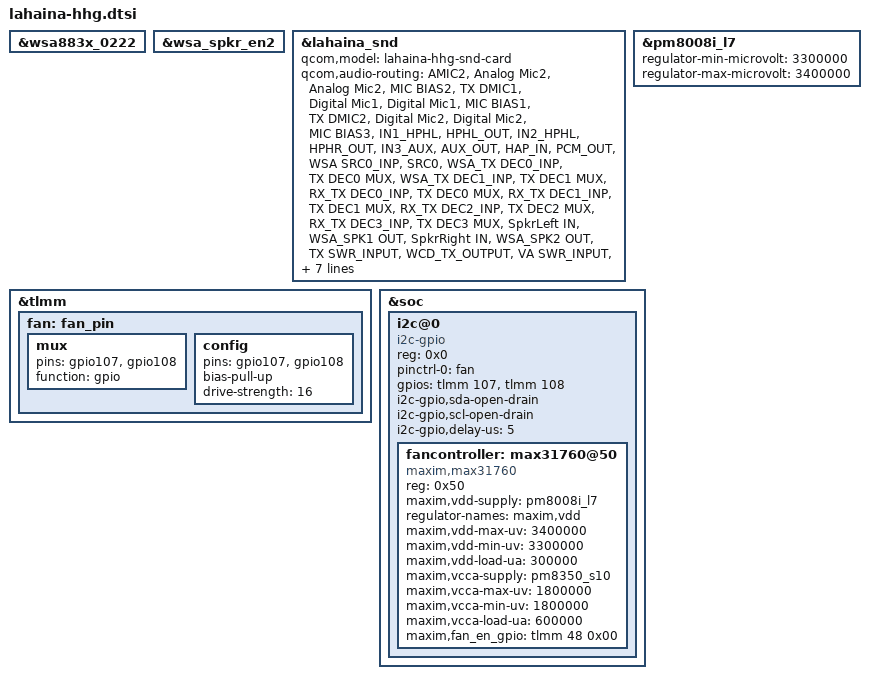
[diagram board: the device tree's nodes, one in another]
#include "lahaina-hdk.dtsi"

&wsa883x_0222 {
	status = "ok";
};

&wsa_spkr_en2 {
	status = "ok";
};

&lahaina_snd {
	qcom,model = "lahaina-hhg-snd-card";

	qcom,audio-routing =
		"AMIC2", "Analog Mic2",
		"Analog Mic2", "MIC BIAS2",
		"TX DMIC1", "Digital Mic1",
		"Digital Mic1", "MIC BIAS1",
		"TX DMIC2", "Digital Mic2",
		"Digital Mic2", "MIC BIAS3",
		"IN1_HPHL", "HPHL_OUT",
		"IN2_HPHL", "HPHR_OUT",
		"IN3_AUX", "AUX_OUT",
		"HAP_IN", "PCM_OUT",
		"WSA SRC0_INP", "SRC0",
		"WSA_TX DEC0_INP", "TX DEC0 MUX",
		"WSA_TX DEC1_INP", "TX DEC1 MUX",
		"RX_TX DEC0_INP", "TX DEC0 MUX",
		"RX_TX DEC1_INP", "TX DEC1 MUX",
		"RX_TX DEC2_INP", "TX DEC2 MUX",
		"RX_TX DEC3_INP", "TX DEC3 MUX",
		"SpkrLeft IN", "WSA_SPK1 OUT",
		"SpkrRight IN", "WSA_SPK2 OUT",
		"TX SWR_INPUT", "WCD_TX_OUTPUT",
		"VA SWR_INPUT", "VA_SWR_CLK",
		"VA SWR_INPUT", "WCD_TX_OUTPUT",
		"VA_AIF1 CAP", "VA_SWR_CLK",
		"VA_AIF2 CAP", "VA_SWR_CLK",
		"VA_AIF3 CAP", "VA_SWR_CLK",
		"VA DMIC1", "Digital Mic1",
		"VA DMIC2", "Digital Mic2",
		"VA DMIC1", "VA MIC BIAS1",
		"VA DMIC2", "VA MIC BIAS2";

	qcom,wsa-max-devs = <2>;
};

&tlmm {
	fan: fan_pin {
		mux {
			pins = "gpio107","gpio108";
			function = "gpio";
		};

		config {
			pins = "gpio107","gpio108";
			bias-pull-up;
			drive-strength = <16>;
		};
	};
};

&pm8008i_l7 {
	regulator-min-microvolt = <3300000>;
	regulator-max-microvolt = <3400000>;
};

&soc {
	i2c@0 {
		compatible = "i2c-gpio";
		reg = <0x0>;
		pinctrl-names = "default";
		pinctrl-0 = <&fan>;
		gpios = <&tlmm 107 (GPIO_ACTIVE_HIGH | GPIO_OPEN_DRAIN) /* sda */>,
			<&tlmm 108 (GPIO_ACTIVE_HIGH | GPIO_OPEN_DRAIN) /* scl */>;

		i2c-gpio,sda-open-drain;
		i2c-gpio,scl-open-drain;
		i2c-gpio,delay-us = <5>;
		#address-cells = <1>;
		#size-cells = <0>;

		fancontroller: max31760@50 {
			compatible = "maxim,max31760";
			reg = <0x50>;
			maxim,vdd-supply = <&pm8008i_l7>;
			regulator-names = "maxim,vdd";
			maxim,vdd-max-uv = <3400000>;
			maxim,vdd-min-uv = <3300000>;
			maxim,vdd-load-ua = <300000>;
			maxim,vcca-supply = <&pm8350_s10>;
			maxim,vcca-max-uv = <1800000>;
			maxim,vcca-min-uv = <1800000>;
			maxim,vcca-load-ua = <600000>;
			maxim,fan_en_gpio = <&tlmm 48 0x00>;
			status = "ok";
		};
	};
};
